CM_ "IMPORT _honda_common.dbc";
CM_ "IMPORT _nidec_common.dbc";
CM_ "IMPORT _steering_sensors_b.dbc";
CM_ "IMPORT _steering_control_a.dbc";

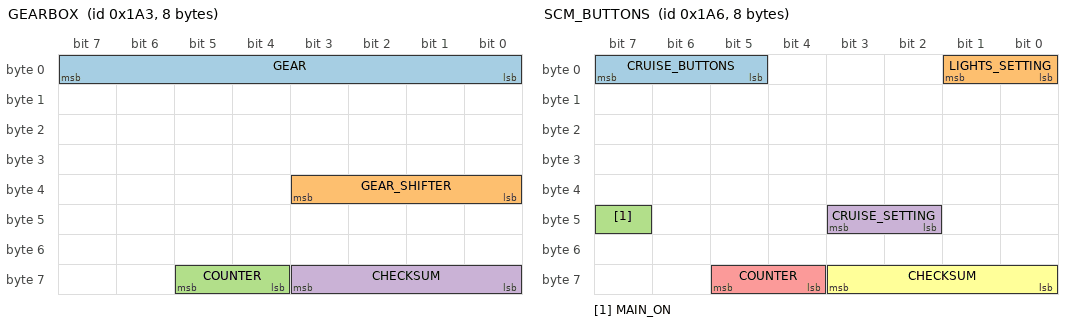
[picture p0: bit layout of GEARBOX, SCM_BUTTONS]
BO_ 419 GEARBOX: 8 PCM
 SG_ GEAR : 7|8@0+ (1,0) [0|256] "" EON
 SG_ GEAR_SHIFTER : 35|4@0+ (1,0) [0|15] "" EON
 SG_ COUNTER : 61|2@0+ (1,0) [0|3] "" EON
 SG_ CHECKSUM : 59|4@0+ (1,0) [0|3] "" EON

BO_ 422 SCM_BUTTONS: 8 SCM
 SG_ CRUISE_BUTTONS : 7|3@0+ (1,0) [0|7] "" EON
 SG_ LIGHTS_SETTING : 1|2@0+ (1,0) [0|3] "" EON
 SG_ MAIN_ON : 47|1@0+ (1,0) [0|1] "" EON
 SG_ CRUISE_SETTING : 43|2@0+ (1,0) [0|3] "" EON
 SG_ COUNTER : 61|2@0+ (1,0) [0|3] "" EON
 SG_ CHECKSUM : 59|4@0+ (1,0) [0|3] "" EON

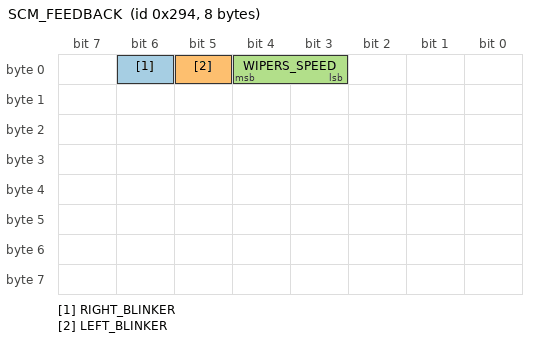
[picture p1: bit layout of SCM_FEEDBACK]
BO_ 660 SCM_FEEDBACK: 8 SCM
 SG_ RIGHT_BLINKER : 6|1@0+ (1,0) [0|1] "" EON
 SG_ LEFT_BLINKER : 5|1@0+ (1,0) [0|1] "" EON
 SG_ WIPERS_SPEED : 4|2@0+ (1,0) [0|3] "" EON

CM_ SG_ 419 GEAR "10 = reverse, 11 = transition";
CM_ SG_ 780 CRUISE_SPEED "255 = no speed";

VAL_ 419 GEAR_SHIFTER 10 "S" 4 "D" 3 "N" 2 "R" 1 "P" ;
VAL_ 422 CRUISE_BUTTONS 7 "tbd" 6 "tbd" 5 "tbd" 4 "accel_res" 3 "decel_set" 2 "cancel" 1 "main" 0 "none" ;
VAL_ 422 LIGHTS_SETTING 3 "high_beam" 2 "low_beam" 1 "position" 0 "no_lights" ;
VAL_ 422 CRUISE_SETTING 3 "distance_adj" 2 "tbd" 1 "lkas_button" 0 "none" ;
VAL_ 506 CHIME 4 "double_chime" 3 "single_chime" 2 "continuous_chime" 1 "repeating_chime" 0 "no_chime" ;
VAL_ 506 FCW 3 "fcw" 2 "fcw" 1 "fcw" 0 "no_fcw" ;
VAL_ 780 HUD_LEAD 3 "no_car" 2 "solid_car" 1 "dashed_car" 0 "no_car" ;
